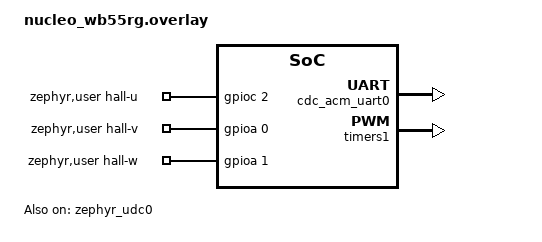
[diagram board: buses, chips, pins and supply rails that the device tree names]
/* Target the timer node to set up the PWM pins */
/ {
    chosen {
        zephyr,console = &cdc_acm_uart0; /* Route terminal to USB */
        zephyr,pwm = &pwm1; 
    };

    zephyr,user {
        hall-u-gpios = <&gpioc 2 GPIO_ACTIVE_HIGH>;
        hall-v-gpios = <&gpioa 0 GPIO_ACTIVE_HIGH>; /* Moved to PA0 */
        hall-w-gpios = <&gpioa 1 GPIO_ACTIVE_HIGH>; 
    };
};

/* The Native USB Node */
&zephyr_udc0 {
    pinctrl-0 = <&usb_dm_pa11 &usb_dp_pa12>;
    pinctrl-names = "default";
    status = "okay";

    cdc_acm_uart0: cdc_acm_uart0 {
        compatible = "zephyr,cdc-acm-uart";
    };
};

&timers1 {
    status = "okay";

    pwm1: pwm {
        status = "okay";
        pinctrl-0 = <&pwm1_ch1_pa8 &pwm1_ch2_pa9 &pwm1_ch3_pa10 
                     &pwm1_ch1n_pb13 &pwm1_ch2n_pb14 &pwm1_ch3n_pb15>;
        pinctrl-names = "default";
    };
};

/* Define the physical pin routing (Alternate Function 1 for TIM1) */
&pinctrl {
    pwm1_ch1_pa8: pwm1_ch1_pa8 {
        pinmux = <STM32_PINMUX('A', 8, AF1)>; 
        bias-pull-down;
    };
    pwm1_ch2_pa9: pwm1_ch2_pa9 {
        pinmux = <STM32_PINMUX('A', 9, AF1)>;   
        bias-pull-down;
    };
    pwm1_ch3_pa10: pwm1_ch3_pa10 {
        pinmux = <STM32_PINMUX('A', 10, AF1)>;  
        bias-pull-down;
    };
    pwm1_ch1n_pb13: pwm1_ch1n_pb13 {
        pinmux = <STM32_PINMUX('B', 13, AF1)>;   
        bias-pull-down;
    };
    pwm1_ch2n_pb14: pwm1_ch2n_pb14 {
        pinmux = <STM32_PINMUX('B', 14, AF1)>;   
        bias-pull-down;
    };
    pwm1_ch3n_pb15: pwm1_ch3n_pb15 {
        pinmux = <STM32_PINMUX('B', 15, AF1)>;   
        bias-pull-down;
    };
};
